# ATSAMC21N18A register map
Registers are 32-bit, access not given, no defined reset value unless marked. A register's access mark holds for its fields unless they carry their own. Addresses are absolute; registers are grouped by the start of their names; [hi:lo] are bit positions; {n}, {i} and the like mark numbered series.

## GCLK
0x40001C00 GCLK_CTRLA 8-bit — Control
  [0] SWRST
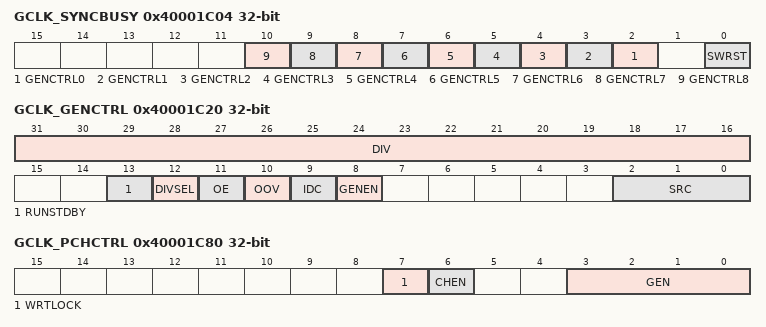
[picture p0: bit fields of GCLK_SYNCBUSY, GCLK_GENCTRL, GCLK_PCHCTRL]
0x40001C04 GCLK_SYNCBUSY — Synchronization Busy
  [n+2] GENCTRL{n} (n=0..8), [0] SWRST
0x40001C20 GCLK_GENCTRL — Generic Clock Generator Control
  [31:16] DIV, [13] RUNSTDBY, [12] DIVSEL, [11] OE, [10] OOV, [9] IDC, [8] GENEN, [2:0] SRC
0x40001C80 GCLK_PCHCTRL — Peripheral Clock Control
  [7] WRTLOCK, [6] CHEN, [3:0] GEN

## HMATRIXHS
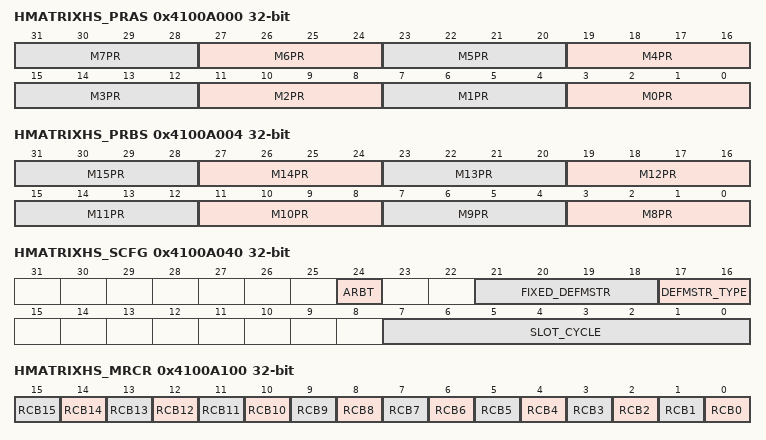
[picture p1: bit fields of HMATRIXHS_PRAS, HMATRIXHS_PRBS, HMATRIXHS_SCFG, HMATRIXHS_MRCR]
0x4100A000 HMATRIXHS_PRAS — Priority A for Slave
  [4n+3:4n] M{n}PR (n=0..7)
0x4100A000 HMATRIXHS_MCFG — Master Configuration
  [2:0] ULBT
0x4100A004 HMATRIXHS_PRBS — Priority B for Slave
  [4n-29:4n-32] M{n}PR (n=8..15)
0x4100A040 HMATRIXHS_SCFG — Slave Configuration
  [24] ARBT, [21:18] FIXED_DEFMSTR, [17:16] DEFMSTR_TYPE, [7:0] SLOT_CYCLE
0x4100A100 HMATRIXHS_MRCR — Master Remap Control
  [n] RCB{n} (n=0..15)
0x4100A110 HMATRIXHS_SFR — Special Function

## MCLK
0x40000801 MCLK_INTENCLR 8-bit — Interrupt Enable Clear
  [0] CKRDY
0x40000802 MCLK_INTENSET 8-bit — Interrupt Enable Set
  [0] CKRDY
0x40000803 MCLK_INTFLAG 8-bit — Interrupt Flag Status and Clear
  [0] CKRDY
0x40000804 MCLK_CPUDIV 8-bit — CPU Clock Division
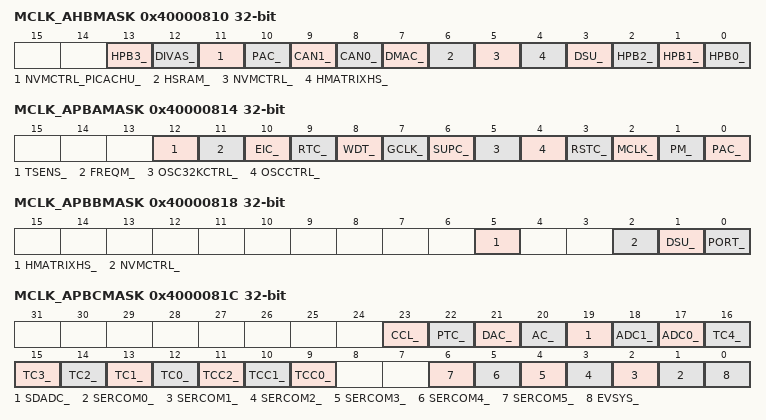
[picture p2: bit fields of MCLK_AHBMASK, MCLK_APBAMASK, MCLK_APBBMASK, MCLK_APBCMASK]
0x40000810 MCLK_AHBMASK — AHB Mask
  [13] HPB3_, [12] DIVAS_, [11] NVMCTRL_PICACHU_, [10] PAC_, [9] CAN1_, [8] CAN0_, [7] DMAC_, [6] HSRAM_, [5] NVMCTRL_, [4] HMATRIXHS_, [3] DSU_, [2] HPB2_, [1] HPB1_, [0] HPB0_
0x40000814 MCLK_APBAMASK — APBA Mask
  [12] TSENS_, [11] FREQM_, [10] EIC_, [9] RTC_, [8] WDT_, [7] GCLK_, [6] SUPC_, [5] OSC32KCTRL_, [4] OSCCTRL_, [3] RSTC_, [2] MCLK_, [1] PM_, [0] PAC_
0x40000818 MCLK_APBBMASK — APBB Mask
  [5] HMATRIXHS_, [2] NVMCTRL_, [1] DSU_, [0] PORT_
0x4000081C MCLK_APBCMASK — APBC Mask
  [23] CCL_, [22] PTC_, [21] DAC_, [20] AC_, [19] SDADC_, [18] ADC1_, [17] ADC0_, [n+12] TC{n}_ (n=0..4), [11] TCC2_, [10] TCC1_, [9] TCC0_, [n+1] SERCOM{n}_ (n=0..5), [0] EVSYS_
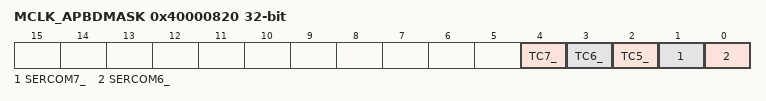
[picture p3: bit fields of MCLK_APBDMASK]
0x40000820 MCLK_APBDMASK — APBD Mask
  [4] TC7_, [3] TC6_, [2] TC5_, [1] SERCOM7_, [0] SERCOM6_

## MTB
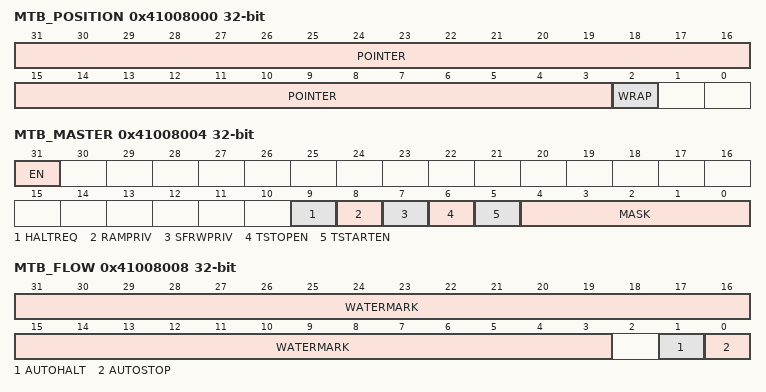
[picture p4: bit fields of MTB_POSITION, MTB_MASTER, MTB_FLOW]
0x41008000 MTB_POSITION
  [31:3] POINTER, [2] WRAP
0x41008004 MTB_MASTER
  [31] EN, [9] HALTREQ, [8] RAMPRIV, [7] SFRWPRIV, [6] TSTOPEN, [5] TSTARTEN, [4:0] MASK
0x41008008 MTB_FLOW
  [31:3] WATERMARK, [1] AUTOHALT, [0] AUTOSTOP
0x4100800C MTB_BASE
0x41008F00 MTB_ITCTRL — MTB Integration Mode Control
0x41008FA0 MTB_CLAIMSET
0x41008FA4 MTB_CLAIMCLR — MTB Claim Clear
0x41008FB0 MTB_LOCKACCESS
0x41008FB4 MTB_LOCKSTATUS
0x41008FB8 MTB_AUTHSTATUS — MTB Authentication Status
0x41008FBC MTB_DEVARCH — MTB Device Architecture
0x41008FC8 MTB_DEVID — MTB Device Configuration
0x41008FCC MTB_DEVTYPE — MTB Device Type
{0x41008FC0+4i} MTB_PID{i} (i=4..7) — Peripheral Identification {i}
{0x41008FE0+4i} MTB_PID{i} (i=0..3) — Peripheral Identification {i}
{0x41008FF0+4i} MTB_CID{i} (i=0..3) — Component Identification {i}

## NVMCTRL
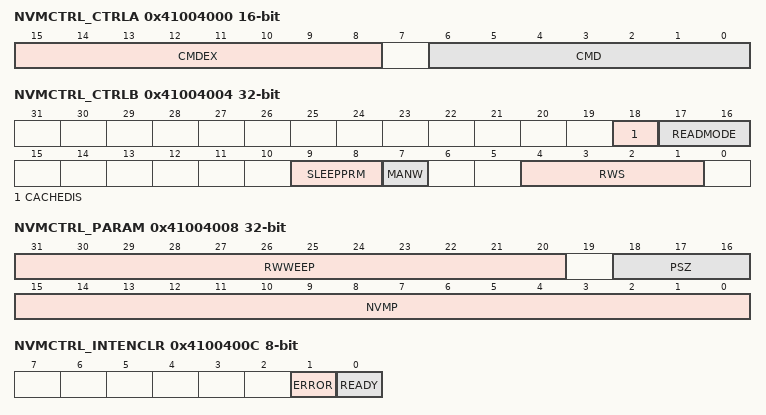
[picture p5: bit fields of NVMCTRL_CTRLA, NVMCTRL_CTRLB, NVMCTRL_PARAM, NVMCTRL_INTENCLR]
0x41004000 NVMCTRL_CTRLA 16-bit — Control A
  [15:8] CMDEX, [6:0] CMD
0x41004004 NVMCTRL_CTRLB — Control B
  [18] CACHEDIS, [17:16] READMODE, [9:8] SLEEPPRM, [7] MANW, [4:1] RWS
0x41004008 NVMCTRL_PARAM — NVM Parameter
  [31:20] RWWEEP, [18:16] PSZ, [15:0] NVMP
0x4100400C NVMCTRL_INTENCLR 8-bit — Interrupt Enable Clear
  [1] ERROR, [0] READY
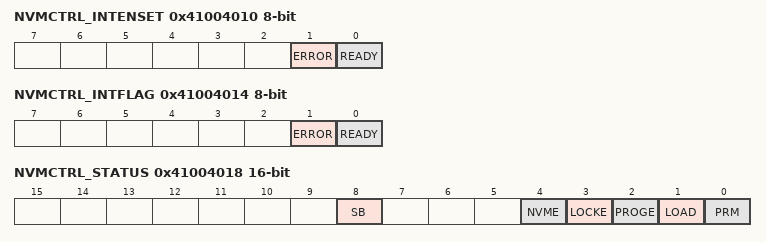
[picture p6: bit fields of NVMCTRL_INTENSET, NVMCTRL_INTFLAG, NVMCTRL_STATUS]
0x41004010 NVMCTRL_INTENSET 8-bit — Interrupt Enable Set
  [1] ERROR, [0] READY
0x41004014 NVMCTRL_INTFLAG 8-bit — Interrupt Flag Status and Clear
  [1] ERROR, [0] READY
0x41004018 NVMCTRL_STATUS 16-bit — Status
  [8] SB, [4] NVME, [3] LOCKE, [2] PROGE, [1] LOAD, [0] PRM
0x4100401C NVMCTRL_ADDR — Address
  [21:0] ADDR
0x41004020 NVMCTRL_LOCK 16-bit — Lock Section
0x41004028 NVMCTRL_PBLDATA0 — Page Buffer Load Data 0
0x4100402C NVMCTRL_PBLDATA1 — Page Buffer Load Data 1
